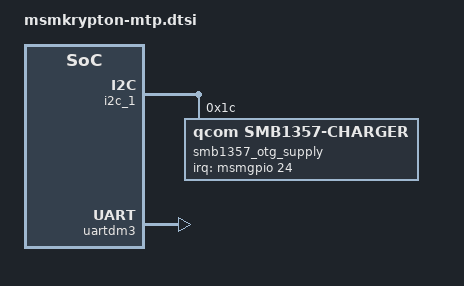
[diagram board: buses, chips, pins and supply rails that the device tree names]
/* Copyright (c) 2013, The Linux Foundation. All rights reserved.
 *
 * This program is free software; you can redistribute it and/or modify
 * it under the terms of the GNU General Public License version 2 and
 * only version 2 as published by the Free Software Foundation.
 *
 * This program is distributed in the hope that it will be useful,
 * but WITHOUT ANY WARRANTY; without even the implied warranty of
 * MERCHANTABILITY or FITNESS FOR A PARTICULAR PURPOSE.  See the
 * GNU General Public License for more details.
 */

&soc {
};

&i2c_1 {
	smb1357_otg_supply: smb1357-charger@1c {
		compatible = "qcom,smb1357-charger";
		reg = <0x1c>;
		interrupt-parent = <&msmgpio>;
		interrupts = <24 0x3>;	/* MDM GPIO 24 */
		qcom,float-voltage-mv = <4200>;
		qcom,charging-timeout = <1536>;
		qcom,recharge-thresh-mv = <200>;
		qcom,iterm-ma = <100>;
		regulator-name = "smb1357_otg_supply";
	};
};

&uartdm3{
	status = "ok";
};
